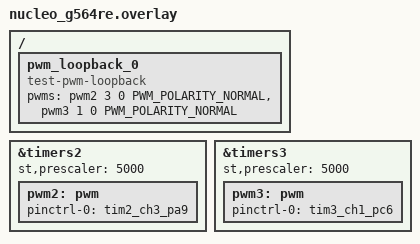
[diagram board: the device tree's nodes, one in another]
/*
 * Copyright (c) 2026 STMicroelectronics
 *
 * SPDX-License-Identifier: Apache-2.0
 */

#include <zephyr/dt-bindings/pwm/pwm.h>

/ {
	pwm_loopback_0 {
		compatible = "test-pwm-loopback";
		/* first index must be a 32-Bit timer */
		pwms = <&pwm2 3 0 PWM_POLARITY_NORMAL>,
		       <&pwm3 1 0 PWM_POLARITY_NORMAL>;
	};
};

&timers2 {
	st,prescaler = <5000>;
	status = "okay";

	pwm2: pwm {
		pinctrl-0 = <&tim2_ch3_pa9>; /* Arduino D6 */
		pinctrl-names = "default";
		status = "okay";
	};
};

&timers3 {
	st,prescaler = <5000>;
	status = "okay";

	pwm3: pwm {
		pinctrl-0 = <&tim3_ch1_pc6>; /* Arduino D7 */
		pinctrl-names = "default";
		status = "okay";
	};
};
